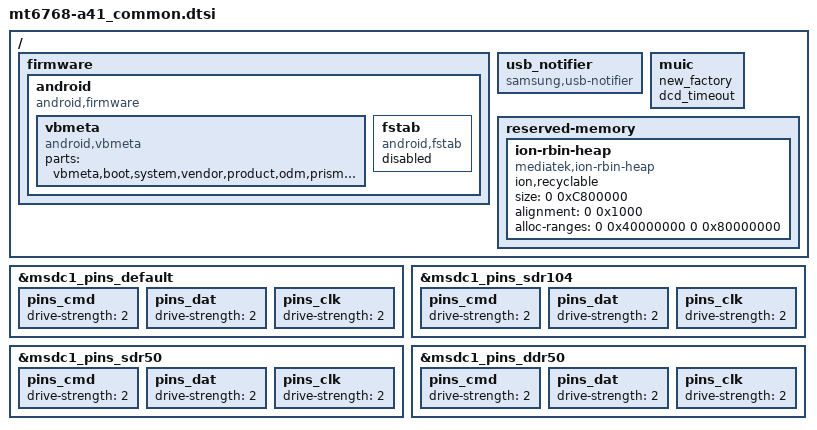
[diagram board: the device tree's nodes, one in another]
/* Generated by Samsung for MTK vendor board 
 * If these files should be changed, then please make a sync with MTK
*/

#include "display_lcd_a41_common.dtsi"

/* Add Samsung configuration over here */
/ {
	fragment@model {
		target-path = "/";
		__overlay__ {
			firmware {
				android {
					compatible = "android,firmware";
					vbmeta {
						compatible = "android,vbmeta";
						parts = "vbmeta,boot,system,vendor,product,odm,prism,optics,vbmeta_samsung,recovery,dtbo,lk,tee1";
					};
					fstab {
						compatible = "android,fstab";
						status = "disabled";
					};
				};
			};

			usb_notifier {
				compatible = "samsung,usb-notifier";
			};
			muic {
				new_factory;
				dcd_timeout;
			};
			reserved-memory {
				ion-rbin-heap {
					compatible = "mediatek,ion-rbin-heap";
					ion,recyclable;
					size = <0 0xC800000>;
					alignment = <0 0x1000>;
					alloc-ranges = <0 0x40000000 0 0x80000000>;
				};
			};			
		};
	};
};

&msdc1_pins_default {
	pins_cmd {
		drive-strength = /bits/ 8 <2>;
	};
	pins_dat {
		drive-strength = /bits/ 8 <2>;
	};
	pins_clk {
		drive-strength = /bits/ 8 <2>;
	};
};

&msdc1_pins_sdr104 {
	pins_cmd {
		drive-strength = /bits/ 8 <2>;
	};
	pins_dat {
		drive-strength = /bits/ 8 <2>;
	};
	pins_clk {
		drive-strength = /bits/ 8 <2>;
	};
};

&msdc1_pins_sdr50 {
	pins_cmd {
		drive-strength = /bits/ 8 <2>;
	};
	pins_dat {
		drive-strength = /bits/ 8 <2>;
	};
	pins_clk {
		drive-strength = /bits/ 8 <2>;
	};
};

&msdc1_pins_ddr50 {
	pins_cmd {
		drive-strength = /bits/ 8 <2>;
	};
	pins_dat {
		drive-strength = /bits/ 8 <2>;
	};
	pins_clk {
		drive-strength = /bits/ 8 <2>;
	};
};

